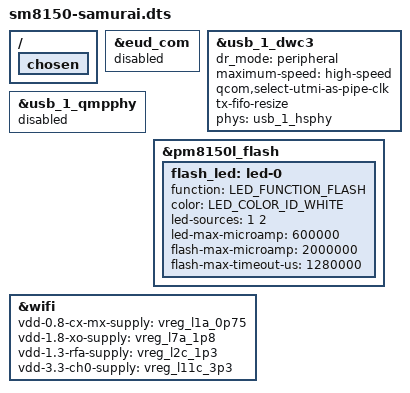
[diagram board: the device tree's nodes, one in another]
// SPDX-License-Identifier: BSD-3-Clause
/*
 * Realme X2 Pro (RMX1931 / samurai), OS-facing board description.
 *
 * The hardware contract is DTS-only.  Debug EUD and test command lines are
 * deliberately not part of the production board description.
 */
/dts-v1/;

#include <dt-bindings/leds/common.h>

#include "sm8150-samurai-common.dtsi"
#include "samurai-sensor-power-data.dtsi"

/ {
	chosen {
		/delete-property/ bootargs;
		/delete-property/ stdout-path;
	};
};

&eud_com {
	status = "disabled";
};

&usb_1_dwc3 {
	status = "okay";
	dr_mode = "peripheral";
	maximum-speed = "high-speed";
	qcom,select-utmi-as-pipe-clk;
	tx-fifo-resize;
	phys = <&usb_1_hsphy>;
	phy-names = "usb2-phy";
};

&usb_1_qmpphy {
	status = "disabled";
};

/*
 * The stock camera description wires the rear dual-LED flash to PM8150L
 * channels 0 and 1.  Describe them as one physical white LED so the
 * standard LED-flash and V4L2-flash APIs expose the combined emitter.
 */
&pm8150l_flash {
	status = "okay";

	flash_led: led-0 {
		function = LED_FUNCTION_FLASH;
		color = <LED_COLOR_ID_WHITE>;
		led-sources = <1 2>;
		led-max-microamp = <600000>;
		flash-max-microamp = <2000000>;
		flash-max-timeout-us = <1280000>;
	};
};

/*
 * The stock samurai DTB binds the WCN3990 WiFi PMU to the same four
 * regulators as the Bluetooth node.  Keep those explicit in the source
 * wrapper for reproducible firmware builds.  The optional fifth ch1 rail
 * is intentionally absent; the driver falls back to a dummy consumer.
 */
&wifi {
	vdd-0.8-cx-mx-supply = <&vreg_l1a_0p75>;
	vdd-1.8-xo-supply = <&vreg_l7a_1p8>;
	vdd-1.3-rfa-supply = <&vreg_l2c_1p3>;
	vdd-3.3-ch0-supply = <&vreg_l11c_3p3>;
	status = "okay";
};
